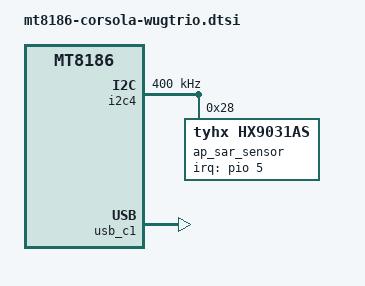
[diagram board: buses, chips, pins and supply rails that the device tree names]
// SPDX-License-Identifier: (GPL-2.0 OR MIT)
/*
 * Copyright 2024 Google LLC
 */

/dts-v1/;
#include "mt8186-corsola-starmie.dtsi"
#include "mt8186-corsola-it6505.dtsi"

/delete-node/ &en_pp6000_mipi_disp_150ma;
/delete-node/ &pp6000_mipi_disp_150ma_fixed_pins;

&i2c4 {
	status = "okay";
	clock-frequency = <400000>;

	ap_sar_sensor: hx9031as@28 {
		compatible = "tyhx,hx9031as";
		reg = <0x28>;
		pinctrl-names = "default";
		pinctrl-0 = <&sar_sensor_pins>;
		interrupt-parent = <&pio>;
		interrupts = <5 IRQ_TYPE_EDGE_FALLING>;
	};
};

&panel {
	/* compatible will be set in board dts */
	pp3300-supply = <&en_pp6000_mipi_disp>;
	/delete-property/ avdd-supply;
	/delete-property/ avee-supply;
	/delete-property/ pp1800-supply;
	rotation = <90>;
};

&pen_insert {
	/* Insert = high, eject = low */
	gpios = <&pio 18 GPIO_ACTIVE_HIGH>;
};

&touchscreen {
	/* ili2900 and ili2901 use the same timing */
	compatible = "ilitek,ili2900", "ilitek,ili2901";
	vccio-supply = <&pp3300_s3>;
};

&mt6366codec {
	mediatek,dmic-mode = <0>; /* two-wire */
};

&pio {
	/* 185 lines */
	gpio-line-names = "TP",
			  "TP",
			  "TP",
			  "I2S0_HP_DI",
			  "I2S3_DP_SPKR_DO",
			  "SAR_INT_ODL",
			  "BT_WAKE_AP_ODL",
			  "WIFI_INT_ODL",
			  "DPBRDG_INT_ODL",
			  "NC",
			  "EC_AP_HPD_OD",
			  "NC",
			  "TCHSCR_INT_1V8_ODL",
			  "EC_AP_INT_ODL",
			  "EC_IN_RW_ODL",
			  "GSC_AP_INT_ODL",
			  /*
			  * AP_FLASH_WP_L is crossystem ABI. Rev1 schematics
			  * call it AP_WP_ODL.
			  */
			  "AP_FLASH_WP_L",
			  "HP_INT_ODL",
			  "PEN_EJECT_OD",
			  "NC",
			  "NC",
			  "UCAM_SEN_EN",
			  "NC",
			  "NC",
			  "NC",
			  "I2S2_DP_SPK_MCK",
			  "I2S2_DP_SPKR_BCK",
			  "I2S2_DP_SPKR_LRCK",
			  "NC",
			  "NC",
			  "NC",
			  "NC",
			  "UART_GSC_TX_AP_RX",
			  "UART_AP_TX_GSC_RX",
			  "UART_DBGCON_TX_ADSP_RX",
			  "UART_ADSP_TX_DBGCON_RX",
			  "NC",
			  "TCHSCR_REPORT_DISABLE",
			  "NC",
			  "EN_PP1800_DPBRDG",
			  "SPI_AP_CLK_EC",
			  "SPI_AP_CS_EC_L",
			  "SPI_AP_DO_EC_DI",
			  "SPI_AP_DI_EC_DO",
			  "SPI_AP_CLK_GSC",
			  "SPI_AP_CS_GSC_L",
			  "SPI_AP_DO_GSC_DI",
			  "SPI_AP_DI_GSC_DO",
			  "UART_DBGCON_TX_SCP_RX",
			  "UART_SCP_TX_DBGCON_RX",
			  "EN_PP1200_CAM_X",
			  "WLAN_MODULE_RST_L",
			  "NC",
			  "NC",
			  "NC",
			  "NC",
			  "I2S1_HP_DO",
			  "I2S1_HP_BCK",
			  "I2S1_HP_LRCK",
			  "I2S1_HP_MCK",
			  "TCHSCR_RST_1V8_L",
			  "SPI_AP_CLK_ROM",
			  "SPI_AP_CS_ROM_L",
			  "SPI_AP_DO_ROM_DI",
			  "SPI_AP_DI_ROM_DO",
			  "NC",
			  "NC",
			  "EMMC_STRB",
			  "EMMC_CLK",
			  "EMMC_CMD",
			  "EMMC_RST_L",
			  "EMMC_DATA0",
			  "EMMC_DATA1",
			  "EMMC_DATA2",
			  "EMMC_DATA3",
			  "EMMC_DATA4",
			  "EMMC_DATA5",
			  "EMMC_DATA6",
			  "EMMC_DATA7",
			  "AP_KPCOL0",
			  "NC",
			  "NC",
			  "NC",
			  "TP",
			  "SDIO_CLK",
			  "SDIO_CMD",
			  "SDIO_DATA0",
			  "SDIO_DATA1",
			  "SDIO_DATA2",
			  "SDIO_DATA3",
			  "NC",
			  "NC",
			  "NC",
			  "NC",
			  "NC",
			  "NC",
			  "NC",
			  "MIPI_BL_PWM_1V8",
			  "DISP_RST_1V8_L",
			  "MIPI_DPI_CLK",
			  "MIPI_DPI_VSYNC",
			  "MIPI_DPI_HSYNC",
			  "MIPI_DPI_DE",
			  "MIPI_DPI_D0",
			  "MIPI_DPI_D1",
			  "MIPI_DPI_D2",
			  "MIPI_DPI_D3",
			  "MIPI_DPI_D4",
			  "MIPI_DPI_D5",
			  "MIPI_DPI_D6",
			  "MIPI_DPI_DA7",
			  "MIPI_DPI_D8",
			  "MIPI_DPI_D9",
			  "MIPI_DPI_D10",
			  "MIPI_DPI_D11",
			  "PCM_BT_CLK",
			  "PCM_BT_SYNC",
			  "PCM_BT_DI",
			  "PCM_BT_DO",
			  "JTAG_TMS_TP",
			  "JTAG_TCK_TP",
			  "JTAG_TDI_TP",
			  "JTAG_TDO_TP",
			  "JTAG_TRSTN_TP",
			  "NC",
			  "NC",
			  "UCAM_DET_ODL",
			  "NC",
			  "NC",
			  "AP_I2C_TCHSCR_SCL_1V8",
			  "AP_I2C_TCHSCR_SDA_1V8",
			  "NC",
			  "NC",
			  "AP_I2C_DPBRDG_SCL_1V8",
			  "AP_I2C_DPBRDG_SDA_1V8",
			  "NC",
			  "NC",
			  "AP_I2C_AUD_SCL_1V8",
			  "AP_I2C_AUD_SDA_1V8",
			  "AP_I2C_DISP_SCL_1V8",
			  "AP_I2C_DISP_SDA_1V8",
			  "NC",
			  "NC",
			  "NC",
			  "NC",
			  "SCP_I2C_SENSOR_SCL_1V8",
			  "SCP_I2C_SENSOR_SDA_1V8",
			  "AP_EC_WARM_RST_REQ",
			  "AP_XHCI_INIT_DONE",
			  "USB3_HUB_RST_L",
			  "EN_SPKR",
			  "BEEP_ON",
			  "AP_DISP_BKLTEN",
			  "EN_PP6000_MIPI_DISP",
			  "EN_PP3300_SDBRDG_X",
			  "BT_KILL_1V8_L",
			  "WIFI_KILL_1V8_L",
			  "PWRAP_SPI0_CSN",
			  "PWRAP_SPI0_CK",
			  "PWRAP_SPI0_MO",
			  "PWRAP_SPI0_MI",
			  "SRCLKENA0",
			  "SRCLKENA1",
			  "SCP_VREQ_VAO",
			  "AP_RTC_CLK32K",
			  "AP_PMIC_WDTRST_L",
			  "AUD_CLK_MOSI",
			  "AUD_SYNC_MOSI",
			  "AUD_DAT_MOSI0",
			  "AUD_DAT_MOSI1",
			  "AUD_CLK_MISO",
			  "AUD_SYNC_MISO",
			  "AUD_DAT_MISO0",
			  "AUD_DAT_MISO1",
			  "NC",
			  "NC",
			  "NC",
			  "DPBRDG_RST_L",
			  "LTE_W_DISABLE_L",
			  "LTE_SAR_DETECT_L",
			  "EN_PP3300_LTE_X",
			  "LTE_PWR_OFF_L",
			  "LTE_RESET_L",
			  "TP",
			  "TP";

};

&usb_c1 {
	status = "okay";
};
